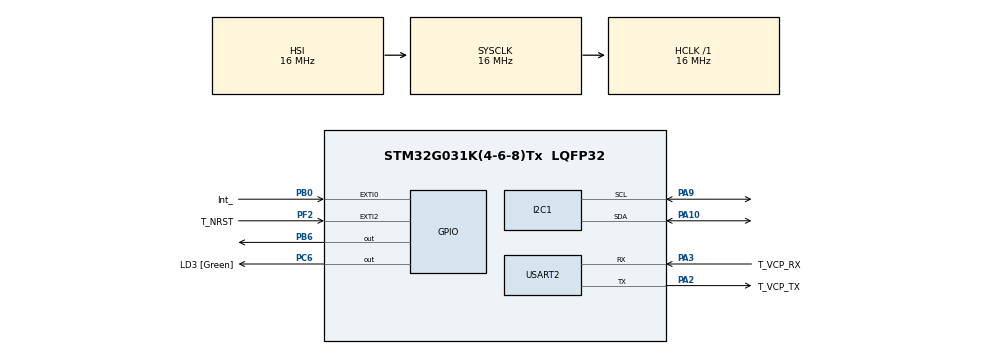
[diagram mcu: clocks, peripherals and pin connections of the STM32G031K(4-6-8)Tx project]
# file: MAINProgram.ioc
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I2C1.Timing=0x00503D58
Mcu.Family=STM32G0
Mcu.Name=STM32G031K(4-6-8)Tx
Mcu.Package=LQFP32
NVIC.EXTI0_1_IRQn=true\:0\:0\:false\:false\:true\:true\:true\:true
PA10.Mode=I2C
PA10.Signal=I2C1_SDA
PA13.GPIO_Label=T_JTMS
PA13.Mode=Serial_Wire
PA13.Signal=SYS_SWDIO
PA14-BOOT0.GPIO_Label=T_JTCK
PA14-BOOT0.Mode=Serial_Wire
PA14-BOOT0.Signal=SYS_SWCLK
PA2.GPIO_Label=T_VCP_TX
PA2.GPIO_PuPd=GPIO_PULLUP
PA2.Mode=Asynchronous
PA2.Signal=USART2_TX
PA3.GPIO_Label=T_VCP_RX
PA3.GPIO_PuPd=GPIO_PULLUP
PA3.Mode=Asynchronous
PA3.Signal=USART2_RX
PA9.Mode=I2C
PA9.Signal=I2C1_SCL
PB0.GPIO_Label=Int_
PB0.GPIO_ModeDefaultEXTI=GPIO_MODE_IT_FALLING
PB0.GPIO_PuPd=GPIO_PULLUP
PB0.Signal=GPXTI0
PB6.Signal=GPIO_Output
PC14-OSC32_IN\ (PC14).Mode=LSE-External-Oscillator
PC14-OSC32_IN\ (PC14).Signal=RCC_OSC32_IN
PC15-OSC32_OUT\ (PC15).Mode=LSE-External-Oscillator
PC15-OSC32_OUT\ (PC15).Signal=RCC_OSC32_OUT
PC6.GPIO_Label=LD3 [Green]
PC6.Signal=GPIO_Output
PF2\ -\ NRST.GPIO_Label=T_NRST
PF2\ -\ NRST.GPIO_ModeDefaultEXTI=GPIO_MODE_IT_RISING
PF2\ -\ NRST.Signal=GPXTI2
ProjectManager.HeapSize=0x200
ProjectManager.StackSize=0x400
ProjectManager.TargetToolchain=EWARM V8.50
RCC.ADCFreq_Value=16000000
RCC.AHBFreq_Value=16000000
RCC.CortexFreq_Value=16000000
RCC.EXTERNAL_CLOCK_VALUE=12288000
RCC.HCLKFreq_Value=16000000
RCC.HSE_VALUE=8000000
RCC.HSI_VALUE=16000000
RCC.SYSCLKFreq_VALUE=16000000
RCC.VCOOutputFreq_Value=128000000
USART2.VirtualMode-Asynchronous=VM_ASYNC
board=NUCLEO-G031K8

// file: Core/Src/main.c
/* USER CODE BEGIN Header */
/**
 ******************************************************************************
 * @file           : main.c
 * @brief          : Main program body
 ******************************************************************************
 * @attention
 *
 * Copyright (c) 2025 STMicroelectronics.
 * All rights reserved.
 *
 * This software is licensed under terms that can be found in the LICENSE file
 * in the root directory of this software component.
 * If no LICENSE file comes with this software, it is provided AS-IS.
 *
 ******************************************************************************
 */
/* USER CODE END Header */
#include "main.h"
#include "max30100_for_stm32_hal.h"
#include "ssd1306.h"
#include "ssd1306_fonts.h"
#include "stdio.h"

/* USER CODE BEGIN Includes */

// 'frame_00_delay-0', 32x32px
const unsigned char epd_bitmap_frame_00_delay_0[] = {
    0xff, 0xff, 0xff, 0xff, 0xff, 0xff, 0xff, 0xff, 0xff, 0xff, 0xff, 0xff, 0xff, 0xff, 0xff, 0xff,
    0xff, 0xff, 0xff, 0xff, 0xff, 0xff, 0xff, 0xff, 0xff, 0x83, 0xe0, 0xff, 0xff, 0x83, 0xe0, 0xff,
    0xff, 0x00, 0xc0, 0x7f, 0xfe, 0x00, 0x80, 0x3f, 0xfc, 0x70, 0x00, 0x1f, 0xf0, 0xf0, 0x00, 0x07,
    0xf0, 0xc0, 0x00, 0x07, 0xf0, 0xc0, 0x00, 0x07, 0xf0, 0x00, 0x00, 0x07, 0xf8, 0x00, 0x00, 0x07,
    0xfc, 0x00, 0x00, 0x1f, 0xff, 0x00, 0x00, 0x3f, 0xff, 0x00, 0x00, 0x7f, 0xff, 0x80, 0x00, 0xff,
    0xff, 0xc0, 0x01, 0xff, 0xff, 0xe0, 0x03, 0xff, 0xff, 0xf8, 0x07, 0xff, 0xff, 0xf8, 0x0f, 0xff,
    0xff, 0xfc, 0x1f, 0xff, 0xff, 0xff, 0x3f, 0xff, 0xff, 0xff, 0x7f, 0xff, 0xff, 0xff, 0xff, 0xff,
    0xff, 0xff, 0xff, 0xff, 0xff, 0xff, 0xff, 0xff, 0xff, 0xff, 0xff, 0xff, 0xff, 0xff, 0xff, 0xff};
// 'frame_01_delay-0', 32x32px
const unsigned char epd_bitmap_frame_01_delay_0[] = {
    0xff, 0xff, 0xff, 0xff, 0xff, 0xff, 0xff, 0xff, 0xff, 0xff, 0xff, 0xff, 0xff, 0xff, 0xff, 0xff,
    0xff, 0xff, 0xff, 0xff, 0xff, 0xff, 0xff, 0xff, 0xff, 0x83, 0xe0, 0xff, 0xff, 0x83, 0xe0, 0xff,
    0xff, 0x00, 0xc0, 0x7f, 0xfe, 0x00, 0x80, 0x3f, 0xfc, 0x70, 0x00, 0x1f, 0xf0, 0xf0, 0x00, 0x07,
    0xf0, 0xc0, 0x00, 0x07, 0xf0, 0xc0, 0x00, 0x07, 0xf0, 0x00, 0x00, 0x07, 0xf8, 0x00, 0x00, 0x07,
    0xfc, 0x00, 0x00, 0x1f, 0xff, 0x00, 0x00, 0x3f, 0xff, 0x00, 0x00, 0x7f, 0xff, 0x80, 0x00, 0xff,
    0xff, 0xc0, 0x01, 0xff, 0xff, 0xe0, 0x03, 0xff, 0xff, 0xf8, 0x07, 0xff, 0xff, 0xf8, 0x0f, 0xff,
    0xff, 0xfc, 0x1f, 0xff, 0xff, 0xff, 0x3f, 0xff, 0xff, 0xff, 0x7f, 0xff, 0xff, 0xff, 0xff, 0xff,
    0xff, 0xff, 0xff, 0xff, 0xff, 0xff, 0xff, 0xff, 0xff, 0xff, 0xff, 0xff, 0xff, 0xff, 0xff, 0xff};
// 'frame_02_delay-0', 32x32px
const unsigned char epd_bitmap_frame_02_delay_0[] = {
    0xff, 0xff, 0xff, 0xff, 0xff, 0xff, 0xff, 0xff, 0xff, 0xff, 0xff, 0xff, 0xff, 0xff, 0xff, 0xff,
    0xff, 0xff, 0xff, 0xff, 0xff, 0xff, 0xff, 0xff, 0xff, 0x83, 0xe0, 0xff, 0xff, 0x83, 0xe0, 0xff,
    0xff, 0x00, 0xc0, 0x7f, 0xfe, 0x00, 0x80, 0x3f, 0xfc, 0x70, 0x00, 0x1f, 0xf0, 0xf0, 0x00, 0x07,
    0xf0, 0xc0, 0x00, 0x07, 0xf0, 0xc0, 0x00, 0x07, 0xf0, 0x00, 0x00, 0x07, 0xf8, 0x00, 0x00, 0x07,
    0xfc, 0x00, 0x00, 0x1f, 0xff, 0x00, 0x00, 0x3f, 0xff, 0x00, 0x00, 0x7f, 0xff, 0x80, 0x00, 0xff,
    0xff, 0xc0, 0x01, 0xff, 0xff, 0xe0, 0x03, 0xff, 0xff, 0xf8, 0x07, 0xff, 0xff, 0xf8, 0x0f, 0xff,
    0xff, 0xfc, 0x1f, 0xff, 0xff, 0xff, 0x3f, 0xff, 0xff, 0xff, 0x7f, 0xff, 0xff, 0xff, 0xff, 0xff,
    0xff, 0xff, 0xff, 0xff, 0xff, 0xff, 0xff, 0xff, 0xff, 0xff, 0xff, 0xff, 0xff, 0xff, 0xff, 0xff};
// 'frame_03_delay-0', 32x32px
const unsigned char epd_bitmap_frame_03_delay_0[] = {
    0xff, 0xff, 0xff, 0xff, 0xff, 0xff, 0xff, 0xff, 0xff, 0xff, 0xff, 0xff, 0xff, 0xff, 0xff, 0xff,
    0xff, 0xff, 0xff, 0xff, 0xff, 0xff, 0xff, 0xff, 0xff, 0x83, 0xe0, 0xff, 0xff, 0x83, 0xe0, 0xff,
    0xff, 0x00, 0xc0, 0x7f, 0xfe, 0x00, 0x80, 0x3f, 0xfc, 0x70, 0x00, 0x1f, 0xf0, 0xf0, 0x00, 0x07,
    0xf0, 0xc0, 0x00, 0x07, 0xf0, 0xc0, 0x00, 0x07, 0xf0, 0x00, 0x00, 0x07, 0xf8, 0x00, 0x00, 0x07,
    0xfc, 0x00, 0x00, 0x1f, 0xff, 0x00, 0x00, 0x3f, 0xff, 0x00, 0x00, 0x7f, 0xff, 0x80, 0x00, 0xff,
    0xff, 0xc0, 0x01, 0xff, 0xff, 0xe0, 0x03, 0xff, 0xff, 0xf8, 0x07, 0xff, 0xff, 0xf8, 0x0f, 0xff,
    0xff, 0xfc, 0x1f, 0xff, 0xff, 0xff, 0x3f, 0xff, 0xff, 0xff, 0x7f, 0xff, 0xff, 0xff, 0xff, 0xff,
    0xff, 0xff, 0xff, 0xff, 0xff, 0xff, 0xff, 0xff, 0xff, 0xff, 0xff, 0xff, 0xff, 0xff, 0xff, 0xff};
// 'frame_04_delay-0', 32x32px
const unsigned char epd_bitmap_frame_04_delay_0[] = {
    0xff, 0xff, 0xff, 0xff, 0xff, 0xff, 0xff, 0xff, 0xff, 0xff, 0xff, 0xff, 0xff, 0xff, 0xff, 0xff,
    0xff, 0xff, 0xff, 0xff, 0xff, 0xff, 0xff, 0xff, 0xff, 0x83, 0xe0, 0xff, 0xff, 0x83, 0xe0, 0xff,
    0xff, 0x00, 0xc0, 0x7f, 0xfe, 0x00, 0x80, 0x3f, 0xfc, 0x70, 0x00, 0x1f, 0xf0, 0xf0, 0x00, 0x07,
    0xf0, 0xc0, 0x00, 0x07, 0xf0, 0xc0, 0x00, 0x07, 0xf0, 0x00, 0x00, 0x07, 0xf8, 0x00, 0x00, 0x07,
    0xfc, 0x00, 0x00, 0x1f, 0xff, 0x00, 0x00, 0x3f, 0xff, 0x00, 0x00, 0x7f, 0xff, 0x80, 0x00, 0xff,
    0xff, 0xc0, 0x01, 0xff, 0xff, 0xe0, 0x03, 0xff, 0xff, 0xf8, 0x07, 0xff, 0xff, 0xf8, 0x0f, 0xff,
    0xff, 0xfc, 0x1f, 0xff, 0xff, 0xff, 0x3f, 0xff, 0xff, 0xff, 0x7f, 0xff, 0xff, 0xff, 0xff, 0xff,
    0xff, 0xff, 0xff, 0xff, 0xff, 0xff, 0xff, 0xff, 0xff, 0xff, 0xff, 0xff, 0xff, 0xff, 0xff, 0xff};
// 'frame_05_delay-0', 32x32px
const unsigned char epd_bitmap_frame_05_delay_0[] = {
    0xff, 0xff, 0xff, 0xff, 0xff, 0xff, 0xff, 0xff, 0xff, 0xff, 0xff, 0xff, 0xff, 0xff, 0xff, 0xff,
    0xff, 0xff, 0xff, 0xff, 0xff, 0xff, 0xff, 0xff, 0xff, 0x83, 0xe0, 0xff, 0xff, 0x83, 0xe0, 0xff,
    0xff, 0x00, 0xc0, 0x7f, 0xfe, 0x00, 0x80, 0x3f, 0xfc, 0x70, 0x00, 0x1f, 0xf0, 0xf0, 0x00, 0x07,
    0xf0, 0xc0, 0x00, 0x07, 0xf0, 0xc0, 0x00, 0x07, 0xf0, 0x00, 0x00, 0x07, 0xf8, 0x00, 0x00, 0x07,
    0xfc, 0x00, 0x00, 0x1f, 0xff, 0x00, 0x00, 0x3f, 0xff, 0x00, 0x00, 0x7f, 0xff, 0x80, 0x00, 0xff,
    0xff, 0xc0, 0x01, 0xff, 0xff, 0xe0, 0x03, 0xff, 0xff, 0xf8, 0x07, 0xff, 0xff, 0xf8, 0x0f, 0xff,
    0xff, 0xfc, 0x1f, 0xff, 0xff, 0xff, 0x3f, 0xff, 0xff, 0xff, 0x7f, 0xff, 0xff, 0xff, 0xff, 0xff,
    0xff, 0xff, 0xff, 0xff, 0xff, 0xff, 0xff, 0xff, 0xff, 0xff, 0xff, 0xff, 0xff, 0xff, 0xff, 0xff};
// 'frame_06_delay-0', 32x32px
const unsigned char epd_bitmap_frame_06_delay_0[] = {
    0xff, 0xff, 0xff, 0xff, 0xff, 0xff, 0xff, 0xff, 0xff, 0xff, 0xff, 0xff, 0xff, 0xff, 0xff, 0xff,
    0xff, 0xff, 0xff, 0xff, 0xff, 0xff, 0xff, 0xff, 0xff, 0x83, 0xe0, 0xff, 0xff, 0x83, 0xe0, 0xff,
    0xff, 0x00, 0xc0, 0x7f, 0xfe, 0x00, 0x80, 0x3f, 0xfc, 0x70, 0x00, 0x1f, 0xf0, 0xf0, 0x00, 0x07,
    0xf0, 0xc0, 0x00, 0x07, 0xf0, 0xc0, 0x00, 0x07, 0xf0, 0x00, 0x00, 0x07, 0xf8, 0x00, 0x00, 0x07,
    0xfc, 0x00, 0x00, 0x1f, 0xff, 0x00, 0x00, 0x3f, 0xff, 0x00, 0x00, 0x7f, 0xff, 0x80, 0x00, 0xff,
    0xff, 0xc0, 0x01, 0xff, 0xff, 0xe0, 0x03, 0xff, 0xff, 0xf8, 0x07, 0xff, 0xff, 0xf8, 0x0f, 0xff,
    0xff, 0xfc, 0x1f, 0xff, 0xff, 0xff, 0x3f, 0xff, 0xff, 0xff, 0x7f, 0xff, 0xff, 0xff, 0xff, 0xff,
    0xff, 0xff, 0xff, 0xff, 0xff, 0xff, 0xff, 0xff, 0xff, 0xff, 0xff, 0xff, 0xff, 0xff, 0xff, 0xff};
// 'frame_07_delay-0', 32x32px
const unsigned char epd_bitmap_frame_07_delay_0[] = {
    0xff, 0xff, 0xff, 0xff, 0xff, 0xff, 0xff, 0xff, 0xff, 0xff, 0xff, 0xff, 0xff, 0xff, 0xff, 0xff,
    0xff, 0xff, 0xff, 0xff, 0xff, 0xff, 0xff, 0xff, 0xff, 0x83, 0xe0, 0xff, 0xff, 0x83, 0xe0, 0xff,
    0xff, 0x00, 0xc0, 0x7f, 0xfe, 0x00, 0x80, 0x3f, 0xfc, 0x70, 0x00, 0x1f, 0xf0, 0xf0, 0x00, 0x07,
    0xf0, 0xc0, 0x00, 0x07, 0xf0, 0xc0, 0x00, 0x07, 0xf0, 0x00, 0x00, 0x07, 0xf8, 0x00, 0x00, 0x07,
    0xfc, 0x00, 0x00, 0x1f, 0xff, 0x00, 0x00, 0x3f, 0xff, 0x00, 0x00, 0x7f, 0xff, 0x80, 0x00, 0xff,
    0xff, 0xc0, 0x01, 0xff, 0xff, 0xe0, 0x03, 0xff, 0xff, 0xf8, 0x07, 0xff, 0xff, 0xf8, 0x0f, 0xff,
    0xff, 0xfc, 0x1f, 0xff, 0xff, 0xff, 0x3f, 0xff, 0xff, 0xff, 0x7f, 0xff, 0xff, 0xff, 0xff, 0xff,
    0xff, 0xff, 0xff, 0xff, 0xff, 0xff, 0xff, 0xff, 0xff, 0xff, 0xff, 0xff, 0xff, 0xff, 0xff, 0xff};
// 'frame_08_delay-0', 32x32px
const unsigned char epd_bitmap_frame_08_delay_0[] = {
    0xff, 0xff, 0xff, 0xff, 0xff, 0xff, 0xff, 0xff, 0xff, 0xff, 0xff, 0xff, 0xff, 0xff, 0xff, 0xff,
    0xff, 0xff, 0xff, 0xff, 0xff, 0xff, 0xff, 0xff, 0xff, 0x83, 0xe0, 0xff, 0xff, 0x83, 0xe0, 0xff,
    0xff, 0x00, 0xc0, 0x7f, 0xfe, 0x00, 0x80, 0x3f, 0xfc, 0x70, 0x00, 0x1f, 0xf0, 0xf0, 0x00, 0x07,
    0xf0, 0xc0, 0x00, 0x07, 0xf0, 0xc0, 0x00, 0x07, 0xf0, 0x00, 0x00, 0x07, 0xf8, 0x00, 0x00, 0x07,
    0xfc, 0x00, 0x00, 0x1f, 0xff, 0x00, 0x00, 0x3f, 0xff, 0x00, 0x00, 0x7f, 0xff, 0x80, 0x00, 0xff,
    0xff, 0xc0, 0x01, 0xff, 0xff, 0xe0, 0x03, 0xff, 0xff, 0xf8, 0x07, 0xff, 0xff, 0xf8, 0x0f, 0xff,
    0xff, 0xfc, 0x1f, 0xff, 0xff, 0xff, 0x3f, 0xff, 0xff, 0xff, 0x7f, 0xff, 0xff, 0xff, 0xff, 0xff,
    0xff, 0xff, 0xff, 0xff, 0xff, 0xff, 0xff, 0xff, 0xff, 0xff, 0xff, 0xff, 0xff, 0xff, 0xff, 0xff};
// 'frame_09_delay-0', 32x32px
const unsigned char epd_bitmap_frame_09_delay_0[] = {
    0xff, 0xff, 0xff, 0xff, 0xff, 0xff, 0xff, 0xff, 0xff, 0xff, 0xff, 0xff, 0xff, 0xff, 0xff, 0xff,
    0xff, 0xff, 0xff, 0xff, 0xff, 0xff, 0xff, 0xff, 0xff, 0x83, 0xe0, 0xff, 0xff, 0x83, 0xe0, 0xff,
    0xff, 0x00, 0xc0, 0x7f, 0xfe, 0x00, 0x80, 0x3f, 0xfc, 0x70, 0x00, 0x1f, 0xf0, 0xf0, 0x00, 0x07,
    0xf0, 0xc0, 0x00, 0x07, 0xf0, 0xc0, 0x00, 0x07, 0xf0, 0x00, 0x00, 0x07, 0xf8, 0x00, 0x00, 0x07,
    0xfc, 0x00, 0x00, 0x1f, 0xff, 0x00, 0x00, 0x3f, 0xff, 0x00, 0x00, 0x7f, 0xff, 0x80, 0x00, 0xff,
    0xff, 0xc0, 0x01, 0xff, 0xff, 0xe0, 0x03, 0xff, 0xff, 0xf8, 0x07, 0xff, 0xff, 0xf8, 0x0f, 0xff,
    0xff, 0xfc, 0x1f, 0xff, 0xff, 0xff, 0x3f, 0xff, 0xff, 0xff, 0x7f, 0xff, 0xff, 0xff, 0xff, 0xff,
    0xff, 0xff, 0xff, 0xff, 0xff, 0xff, 0xff, 0xff, 0xff, 0xff, 0xff, 0xff, 0xff, 0xff, 0xff, 0xff};
// 'frame_10_delay-0', 32x32px
const unsigned char epd_bitmap_frame_10_delay_0[] = {
    0xff, 0xff, 0xff, 0xff, 0xff, 0xff, 0xff, 0xff, 0xff, 0xff, 0xff, 0xff, 0xff, 0xff, 0xff, 0xff,
    0xff, 0xff, 0xff, 0xff, 0xff, 0xff, 0xff, 0xff, 0xff, 0x83, 0xe0, 0xff, 0xff, 0x83, 0xe0, 0xff,
    0xff, 0x00, 0xc0, 0x7f, 0xfe, 0x00, 0x80, 0x3f, 0xfc, 0x70, 0x00, 0x1f, 0xf0, 0xf0, 0x00, 0x07,
    0xf0, 0xc0, 0x00, 0x07, 0xf0, 0xc0, 0x00, 0x07, 0xf0, 0x00, 0x00, 0x07, 0xf8, 0x00, 0x00, 0x07,
    0xfc, 0x00, 0x00, 0x1f, 0xff, 0x00, 0x00, 0x3f, 0xff, 0x00, 0x00, 0x7f, 0xff, 0x80, 0x00, 0xff,
    0xff, 0xc0, 0x01, 0xff, 0xff, 0xe0, 0x03, 0xff, 0xff, 0xf8, 0x07, 0xff, 0xff, 0xf8, 0x0f, 0xff,
    0xff, 0xfc, 0x1f, 0xff, 0xff, 0xff, 0x3f, 0xff, 0xff, 0xff, 0x7f, 0xff, 0xff, 0xff, 0xff, 0xff,
    0xff, 0xff, 0xff, 0xff, 0xff, 0xff, 0xff, 0xff, 0xff, 0xff, 0xff, 0xff, 0xff, 0xff, 0xff, 0xff};
// 'frame_11_delay-0', 32x32px
const unsigned char epd_bitmap_frame_11_delay_0[] = {
    0xff, 0xff, 0xff, 0xff, 0xff, 0xff, 0xff, 0xff, 0xff, 0xff, 0xff, 0xff, 0xff, 0xff, 0xff, 0xff,
    0xff, 0xff, 0xff, 0xff, 0xff, 0xff, 0xff, 0xff, 0xff, 0x83, 0xe0, 0xff, 0xff, 0x83, 0xe0, 0xff,
    0xff, 0x00, 0xc0, 0x7f, 0xfe, 0x00, 0x80, 0x3f, 0xfc, 0x70, 0x00, 0x1f, 0xf0, 0xf0, 0x00, 0x07,
    0xf0, 0xc0, 0x00, 0x07, 0xf0, 0xc0, 0x00, 0x07, 0xf0, 0x00, 0x00, 0x07, 0xf8, 0x00, 0x00, 0x07,
    0xfc, 0x00, 0x00, 0x1f, 0xff, 0x00, 0x00, 0x3f, 0xff, 0x00, 0x00, 0x7f, 0xff, 0x80, 0x00, 0xff,
    0xff, 0xc0, 0x01, 0xff, 0xff, 0xe0, 0x03, 0xff, 0xff, 0xf8, 0x07, 0xff, 0xff, 0xf8, 0x0f, 0xff,
    0xff, 0xfc, 0x1f, 0xff, 0xff, 0xff, 0x3f, 0xff, 0xff, 0xff, 0x7f, 0xff, 0xff, 0xff, 0xff, 0xff,
    0xff, 0xff, 0xff, 0xff, 0xff, 0xff, 0xff, 0xff, 0xff, 0xff, 0xff, 0xff, 0xff, 0xff, 0xff, 0xff};
// 'frame_12_delay-0', 32x32px
const unsigned char epd_bitmap_frame_12_delay_0[] = {
    0xff, 0xff, 0xff, 0xff, 0xff, 0xff, 0xff, 0xff, 0xff, 0xff, 0xff, 0xff, 0xff, 0xff, 0xff, 0xff,
    0xff, 0xff, 0xff, 0xff, 0xff, 0xff, 0xff, 0xff, 0xff, 0x83, 0xe0, 0xff, 0xff, 0x83, 0xe0, 0x7f,
    0xfe, 0x01, 0xc0, 0x3f, 0xfc, 0x70, 0x00, 0x1f, 0xfc, 0x70, 0x00, 0x1f, 0xf0, 0xf0, 0x00, 0x07,
    0xf0, 0xc0, 0x00, 0x07, 0xf0, 0xc0, 0x00, 0x07, 0xf0, 0x00, 0x00, 0x07, 0xf0, 0x00, 0x00, 0x07,
    0xfc, 0x00, 0x00, 0x1f, 0xfe, 0x00, 0x00, 0x3f, 0xfe, 0x00, 0x00, 0x3f, 0xff, 0x80, 0x00, 0xff,
    0xff, 0x80, 0x00, 0xff, 0xff, 0xe0, 0x03, 0xff, 0xff, 0xf0, 0x07, 0xff, 0xff, 0xf8, 0x07, 0xff,
    0xff, 0xfc, 0x1f, 0xff, 0xff, 0xfc, 0x1f, 0xff, 0xff, 0xff, 0x7f, 0xff, 0xff, 0xff, 0xff, 0xff,
    0xff, 0xff, 0xff, 0xff, 0xff, 0xff, 0xff, 0xff, 0xff, 0xff, 0xff, 0xff, 0xff, 0xff, 0xff, 0xff};
// 'frame_14_delay-0', 32x32px
const unsigned char epd_bitmap_frame_14_delay_0[] = {
    0xff, 0xff, 0xff, 0xff, 0xff, 0xff, 0xff, 0xff, 0xff, 0xff, 0xff, 0xff, 0xff, 0xff, 0xff, 0xff,
    0xff, 0xff, 0xff, 0xff, 0xff, 0x83, 0xf0, 0x7f, 0xff, 0x83, 0xf0, 0x7f, 0xfe, 0x01, 0xc0, 0x3f,
    0xfe, 0x00, 0xc0, 0x1f, 0xf8, 0x70, 0x00, 0x0f, 0xf8, 0x70, 0x00, 0x07, 0xe1, 0xe0, 0x00, 0x03,
    0xe1, 0xc0, 0x00, 0x03, 0xe0, 0x00, 0x00, 0x03, 0xe0, 0x00, 0x00, 0x03, 0xf0, 0x00, 0x00, 0x07,
    0xf8, 0x00, 0x00, 0x0f, 0xfe, 0x00, 0x00, 0x1f, 0xfe, 0x00, 0x00, 0x3f, 0xff, 0x80, 0x00, 0x7f,
    0xff, 0x80, 0x00, 0x7f, 0xff, 0xe0, 0x01, 0xff, 0xff, 0xe0, 0x01, 0xff, 0xff, 0xf0, 0x07, 0xff,
    0xff, 0xf0, 0x07, 0xff, 0xff, 0xfc, 0x1f, 0xff, 0xff, 0xff, 0x3f, 0xff, 0xff, 0xff, 0x7f, 0xff,
    0xff, 0xff, 0xff, 0xff, 0xff, 0xff, 0xff, 0xff, 0xff, 0xff, 0xff, 0xff, 0xff, 0xff, 0xff, 0xff};
// 'frame_13_delay-0', 32x32px
const unsigned char epd_bitmap_frame_13_delay_0[] = {
    0xff, 0xff, 0xff, 0xff, 0xff, 0xff, 0xff, 0xff, 0xff, 0xff, 0xff, 0xff, 0xff, 0xff, 0xff, 0xff,
    0xff, 0xff, 0xff, 0xff, 0xff, 0x87, 0xf0, 0xff, 0xff, 0x83, 0xf0, 0xff, 0xfe, 0x01, 0xc0, 0x3f,
    0xfe, 0x00, 0xc0, 0x3f, 0xf8, 0x70, 0x00, 0x0f, 0xf8, 0x70, 0x00, 0x0f, 0xf1, 0xf0, 0x00, 0x03,
    0xf1, 0xc0, 0x00, 0x03, 0xf0, 0xc0, 0x00, 0x03, 0xf0, 0x00, 0x00, 0x03, 0xf0, 0x00, 0x00, 0x07,
    0xf8, 0x00, 0x00, 0x0f, 0xfe, 0x00, 0x00, 0x3f, 0xfe, 0x00, 0x00, 0x3f, 0xff, 0x80, 0x00, 0xff,
    0xff, 0x80, 0x00, 0xff, 0xff, 0xe0, 0x03, 0xff, 0xff, 0xe0, 0x03, 0xff, 0xff, 0xf0, 0x07, 0xff,
    0xff, 0xfc, 0x1f, 0xff, 0xff, 0xfc, 0x1f, 0xff, 0xff, 0xff, 0x7f, 0xff, 0xff, 0xff, 0x7f, 0xff,
    0xff, 0xff, 0xff, 0xff, 0xff, 0xff, 0xff, 0xff, 0xff, 0xff, 0xff, 0xff, 0xff, 0xff, 0xff, 0xff};
// 'frame_15_delay-0', 32x32px
const unsigned char epd_bitmap_frame_15_delay_0[] = {
    0xff, 0xff, 0xff, 0xff, 0xff, 0xff, 0xff, 0xff, 0xff, 0xff, 0xff, 0xff, 0xff, 0xff, 0xff, 0xff,
    0xff, 0xff, 0xff, 0xff, 0xff, 0x03, 0xf0, 0x7f, 0xff, 0x03, 0xe0, 0x7f, 0xfe, 0x01, 0xc0, 0x1f,
    0xfc, 0x00, 0x80, 0x1f, 0xf8, 0x60, 0x00, 0x0f, 0xe0, 0x60, 0x00, 0x03, 0xe1, 0xc0, 0x00, 0x03,
    0xe1, 0xc0, 0x00, 0x03, 0xe0, 0x00, 0x00, 0x03, 0xe0, 0x00, 0x00, 0x03, 0xf0, 0x00, 0x00, 0x07,
    0xf8, 0x00, 0x00, 0x0f, 0xfc, 0x00, 0x00, 0x1f, 0xfe, 0x00, 0x00, 0x1f, 0xff, 0x00, 0x00, 0x7f,
    0xff, 0x00, 0x00, 0x7f, 0xff, 0xc0, 0x01, 0xff, 0xff, 0xc0, 0x01, 0xff, 0xff, 0xf0, 0x07, 0xff,
    0xff, 0xf0, 0x07, 0xff, 0xff, 0xfc, 0x1f, 0xff, 0xff, 0xfc, 0x1f, 0xff, 0xff, 0xff, 0x7f, 0xff,
    0xff, 0xff, 0x7f, 0xff, 0xff, 0xff, 0xff, 0xff, 0xff, 0xff, 0xff, 0xff, 0xff, 0xff, 0xff, 0xff};
// 'frame_17_delay-0', 32x32px
const unsigned char epd_bitmap_frame_17_delay_0[] = {
    0xff, 0xff, 0xff, 0xff, 0xff, 0xff, 0xff, 0xff, 0xff, 0xff, 0xff, 0xff, 0xff, 0xff, 0xff, 0xff,
    0xff, 0x07, 0xf0, 0x7f, 0xff, 0x07, 0xf0, 0x7f, 0xfc, 0x01, 0xc0, 0x1f, 0xfc, 0x01, 0xc0, 0x1f,
    0xf0, 0xe0, 0x00, 0x07, 0xf0, 0xe0, 0x00, 0x07, 0xc3, 0xe0, 0x00, 0x01, 0xc3, 0x80, 0x00, 0x01,
    0xc3, 0x80, 0x00, 0x01, 0xc0, 0x00, 0x00, 0x01, 0xc0, 0x00, 0x00, 0x01, 0xf0, 0x00, 0x00, 0x03,
    0xf0, 0x00, 0x00, 0x07, 0xfc, 0x00, 0x00, 0x0f, 0xfc, 0x00, 0x00, 0x1f, 0xff, 0x00, 0x00, 0x3f,
    0xff, 0x00, 0x00, 0x7f, 0xff, 0xc0, 0x01, 0xff, 0xff, 0xc0, 0x01, 0xff, 0xff, 0xf0, 0x07, 0xff,
    0xff, 0xf0, 0x07, 0xff, 0xff, 0xfc, 0x1f, 0xff, 0xff, 0xfc, 0x1f, 0xff, 0xff, 0xff, 0x7f, 0xff,
    0xff, 0xff, 0x7f, 0xff, 0xff, 0xff, 0xff, 0xff, 0xff, 0xff, 0xff, 0xff, 0xff, 0xff, 0xff, 0xff};
// 'frame_16_delay-0', 32x32px
const unsigned char epd_bitmap_frame_16_delay_0[] = {
    0xff, 0xff, 0xff, 0xff, 0xff, 0xff, 0xff, 0xff, 0xff, 0xff, 0xff, 0xff, 0xff, 0xff, 0xff, 0xff,
    0xff, 0x07, 0xf0, 0x7f, 0xff, 0x07, 0xf0, 0x7f, 0xfc, 0x01, 0xc0, 0x1f, 0xfc, 0x01, 0xc0, 0x1f,
    0xf0, 0x60, 0x00, 0x07, 0xf0, 0xe0, 0x00, 0x07, 0xc1, 0xe0, 0x00, 0x01, 0xc3, 0x80, 0x00, 0x01,
    0xc3, 0x80, 0x00, 0x01, 0xc0, 0x00, 0x00, 0x01, 0xc0, 0x00, 0x00, 0x01, 0xf0, 0x00, 0x00, 0x07,
    0xf0, 0x00, 0x00, 0x07, 0xfc, 0x00, 0x00, 0x1f, 0xfc, 0x00, 0x00, 0x1f, 0xff, 0x00, 0x00, 0x7f,
    0xff, 0x00, 0x00, 0x7f, 0xff, 0xc0, 0x01, 0xff, 0xff, 0xc0, 0x01, 0xff, 0xff, 0xf0, 0x07, 0xff,
    0xff, 0xf0, 0x07, 0xff, 0xff, 0xfc, 0x1f, 0xff, 0xff, 0xfc, 0x1f, 0xff, 0xff, 0xff, 0x7f, 0xff,
    0xff, 0xff, 0x7f, 0xff, 0xff, 0xff, 0xff, 0xff, 0xff, 0xff, 0xff, 0xff, 0xff, 0xff, 0xff, 0xff};
// 'frame_18_delay-0', 32x32px
const unsigned char epd_bitmap_frame_18_delay_0[] = {
    0xff, 0xff, 0xff, 0xff, 0xff, 0xff, 0xff, 0xff, 0xff, 0xff, 0xff, 0xff, 0xff, 0xff, 0xff, 0xff,
    0xff, 0x07, 0xf0, 0x7f, 0xff, 0x03, 0xf0, 0x3f, 0xfc, 0x01, 0xc0, 0x0f, 0xfc, 0x00, 0xc0, 0x0f,
    0xf0, 0xe0, 0x00, 0x03, 0xf0, 0xe0, 0x00, 0x03, 0xc3, 0xe0, 0x00, 0x00, 0xc3, 0x80, 0x00, 0x00,
    0xc3, 0x80, 0x00, 0x00, 0xc0, 0x00, 0x00, 0x00, 0xc0, 0x00, 0x00, 0x00, 0xe0, 0x00, 0x00, 0x03,
    0xf0, 0x00, 0x00, 0x03, 0xf8, 0x00, 0x00, 0x0f, 0xfc, 0x00, 0x00, 0x0f, 0xfe, 0x00, 0x00, 0x3f,
    0xff, 0x00, 0x00, 0x7f, 0xff, 0x80, 0x00, 0xff, 0xff, 0xc0, 0x01, 0xff, 0xff, 0xc0, 0x01, 0xff,
    0xff, 0xf0, 0x07, 0xff, 0xff, 0xf0, 0x07, 0xff, 0xff, 0xfc, 0x1f, 0xff, 0xff, 0xfc, 0x1f, 0xff,
    0xff, 0xff, 0x7f, 0xff, 0xff, 0xff, 0x7f, 0xff, 0xff, 0xff, 0xff, 0xff, 0xff, 0xff, 0xff, 0xff};
// 'frame_20_delay-0', 32x32px
const unsigned char epd_bitmap_frame_20_delay_0[] = {
    0xff, 0xff, 0xff, 0xff, 0xff, 0xff, 0xff, 0xff, 0xff, 0xff, 0xff, 0xff, 0xff, 0xff, 0xff, 0xff,
    0xff, 0x07, 0xf0, 0x7f, 0xff, 0x07, 0xf0, 0x7f, 0xfc, 0x01, 0xc0, 0x1f, 0xfc, 0x01, 0xc0, 0x1f,
    0xf0, 0xe0, 0x00, 0x07, 0xf0, 0xe0, 0x00, 0x07, 0xc3, 0xe0, 0x00, 0x01, 0xc3, 0x80, 0x00, 0x01,
    0xc3, 0x80, 0x00, 0x01, 0xc0, 0x00, 0x00, 0x01, 0xc0, 0x00, 0x00, 0x01, 0xf0, 0x00, 0x00, 0x03,
    0xf0, 0x00, 0x00, 0x07, 0xfc, 0x00, 0x00, 0x0f, 0xfc, 0x00, 0x00, 0x1f, 0xff, 0x00, 0x00, 0x3f,
    0xff, 0x00, 0x00, 0x7f, 0xff, 0xc0, 0x01, 0xff, 0xff, 0xc0, 0x01, 0xff, 0xff, 0xf0, 0x07, 0xff,
    0xff, 0xf0, 0x07, 0xff, 0xff, 0xfc, 0x1f, 0xff, 0xff, 0xfc, 0x1f, 0xff, 0xff, 0xff, 0x7f, 0xff,
    0xff, 0xff, 0x7f, 0xff, 0xff, 0xff, 0xff, 0xff, 0xff, 0xff, 0xff, 0xff, 0xff, 0xff, 0xff, 0xff};
// 'frame_19_delay-0', 32x32px
const unsigned char epd_bitmap_frame_19_delay_0[] = {
    0xff, 0xff, 0xff, 0xff, 0xff, 0xff, 0xff, 0xff, 0xff, 0xff, 0xff, 0xff, 0xff, 0xff, 0xff, 0xff,
    0xff, 0x07, 0xf0, 0x7f, 0xff, 0x07, 0xf0, 0x7f, 0xfc, 0x01, 0xc0, 0x1f, 0xfc, 0x01, 0xc0, 0x1f,
    0xf0, 0xe0, 0x00, 0x07, 0xf0, 0xe0, 0x00, 0x07, 0xc3, 0xe0, 0x00, 0x01, 0xc3, 0x80, 0x00, 0x01,
    0xc3, 0x80, 0x00, 0x01, 0xc0, 0x00, 0x00, 0x01, 0xc0, 0x00, 0x00, 0x01, 0xe0, 0x00, 0x00, 0x03,
    0xf0, 0x00, 0x00, 0x07, 0xfc, 0x00, 0x00, 0x0f, 0xfc, 0x00, 0x00, 0x1f, 0xff, 0x00, 0x00, 0x3f,
    0xff, 0x00, 0x00, 0x7f, 0xff, 0xc0, 0x00, 0xff, 0xff, 0xc0, 0x01, 0xff, 0xff, 0xf0, 0x03, 0xff,
    0xff, 0xf0, 0x07, 0xff, 0xff, 0xfc, 0x0f, 0xff, 0xff, 0xfc, 0x1f, 0xff, 0xff, 0xff, 0x3f, 0xff,
    0xff, 0xff, 0x7f, 0xff, 0xff, 0xff, 0xff, 0xff, 0xff, 0xff, 0xff, 0xff, 0xff, 0xff, 0xff, 0xff};
// 'frame_23_delay-0', 32x32px
const unsigned char epd_bitmap_frame_23_delay_0[] = {
    0xff, 0xff, 0xff, 0xff, 0xff, 0xff, 0xff, 0xff, 0xff, 0xff, 0xff, 0xff, 0xff, 0xff, 0xff, 0xff,
    0xff, 0xff, 0xff, 0xff, 0xff, 0x07, 0xf0, 0x7f, 0xff, 0x03, 0xe0, 0x3f, 0xfc, 0x01, 0xc0, 0x1f,
    0xf8, 0x00, 0x00, 0x07, 0xf8, 0x60, 0x00, 0x07, 0xe0, 0xe0, 0x00, 0x01, 0xe1, 0x80, 0x00, 0x01,
    0xe1, 0x80, 0x00, 0x01, 0xe0, 0x00, 0x00, 0x01, 0xe0, 0x00, 0x00, 0x01, 0xf0, 0x00, 0x00, 0x07,
    0xf8, 0x00, 0x00, 0x07, 0xfc, 0x00, 0x00, 0x1f, 0xfc, 0x00, 0x00, 0x1f, 0xff, 0x00, 0x00, 0x7f,
    0xff, 0x00, 0x00, 0x7f, 0xff, 0xc0, 0x01, 0xff, 0xff, 0xc0, 0x01, 0xff, 0xff, 0xf0, 0x07, 0xff,
    0xff, 0xf0, 0x07, 0xff, 0xff, 0xfc, 0x1f, 0xff, 0xff, 0xfc, 0x1f, 0xff, 0xff, 0xff, 0x7f, 0xff,
    0xff, 0xff, 0x7f, 0xff, 0xff, 0xff, 0xff, 0xff, 0xff, 0xff, 0xff, 0xff, 0xff, 0xff, 0xff, 0xff};
// 'frame_24_delay-0', 32x32px
const unsigned char epd_bitmap_frame_24_delay_0[] = {
    0xff, 0xff, 0xff, 0xff, 0xff, 0xff, 0xff, 0xff, 0xff, 0xff, 0xff, 0xff, 0xff, 0xff, 0xff, 0xff,
    0xff, 0xff, 0xff, 0xff, 0xff, 0x03, 0xf0, 0x7f, 0xff, 0x03, 0xe0, 0x7f, 0xfe, 0x01, 0xc0, 0x1f,
    0xfc, 0x00, 0x80, 0x1f, 0xf8, 0x60, 0x00, 0x0f, 0xe0, 0x60, 0x00, 0x03, 0xe1, 0xc0, 0x00, 0x03,
    0xe1, 0xc0, 0x00, 0x03, 0xe0, 0x00, 0x00, 0x03, 0xe0, 0x00, 0x00, 0x03, 0xf0, 0x00, 0x00, 0x07,
    0xf8, 0x00, 0x00, 0x0f, 0xfc, 0x00, 0x00, 0x1f, 0xfe, 0x00, 0x00, 0x1f, 0xff, 0x00, 0x00, 0x7f,
    0xff, 0x00, 0x00, 0x7f, 0xff, 0xc0, 0x01, 0xff, 0xff, 0xc0, 0x01, 0xff, 0xff, 0xf0, 0x07, 0xff,
    0xff, 0xf0, 0x07, 0xff, 0xff, 0xfc, 0x1f, 0xff, 0xff, 0xfc, 0x1f, 0xff, 0xff, 0xff, 0x7f, 0xff,
    0xff, 0xff, 0x7f, 0xff, 0xff, 0xff, 0xff, 0xff, 0xff, 0xff, 0xff, 0xff, 0xff, 0xff, 0xff, 0xff};
// 'frame_22_delay-0', 32x32px
const unsigned char epd_bitmap_frame_22_delay_0[] = {
    0xff, 0xff, 0xff, 0xff, 0xff, 0xff, 0xff, 0xff, 0xff, 0xff, 0xff, 0xff, 0xff, 0xff, 0xff, 0xff,
    0xff, 0x07, 0xf0, 0x7f, 0xff, 0x07, 0xf0, 0x7f, 0xfc, 0x01, 0xc0, 0x1f, 0xfc, 0x01, 0xc0, 0x1f,
    0xf0, 0x60, 0x00, 0x07, 0xf0, 0xe0, 0x00, 0x07, 0xc1, 0xe0, 0x00, 0x01, 0xc3, 0x80, 0x00, 0x01,
    0xc3, 0x80, 0x00, 0x01, 0xc0, 0x00, 0x00, 0x01, 0xc0, 0x00, 0x00, 0x01, 0xf0, 0x00, 0x00, 0x07,
    0xf0, 0x00, 0x00, 0x07, 0xfc, 0x00, 0x00, 0x1f, 0xfc, 0x00, 0x00, 0x1f, 0xff, 0x00, 0x00, 0x7f,
    0xff, 0x00, 0x00, 0x7f, 0xff, 0xc0, 0x01, 0xff, 0xff, 0xc0, 0x01, 0xff, 0xff, 0xf0, 0x07, 0xff,
    0xff, 0xf0, 0x07, 0xff, 0xff, 0xfc, 0x1f, 0xff, 0xff, 0xfc, 0x1f, 0xff, 0xff, 0xff, 0x7f, 0xff,
    0xff, 0xff, 0x7f, 0xff, 0xff, 0xff, 0xff, 0xff, 0xff, 0xff, 0xff, 0xff, 0xff, 0xff, 0xff, 0xff};
// 'frame_25_delay-0', 32x32px
const unsigned char epd_bitmap_frame_25_delay_0[] = {
    0xff, 0xff, 0xff, 0xff, 0xff, 0xff, 0xff, 0xff, 0xff, 0xff, 0xff, 0xff, 0xff, 0xff, 0xff, 0xff,
    0xff, 0xff, 0xff, 0xff, 0xff, 0x83, 0xf0, 0x7f, 0xff, 0x03, 0xf0, 0x7f, 0xfe, 0x01, 0xc0, 0x3f,
    0xfc, 0x00, 0xc0, 0x1f, 0xf8, 0x60, 0x00, 0x0f, 0xf0, 0x60, 0x00, 0x07, 0xe1, 0xe0, 0x00, 0x03,
    0xe1, 0xc0, 0x00, 0x03, 0xe0, 0x00, 0x00, 0x03, 0xe0, 0x00, 0x00, 0x03, 0xf0, 0x00, 0x00, 0x07,
    0xf8, 0x00, 0x00, 0x0f, 0xfc, 0x00, 0x00, 0x1f, 0xfe, 0x00, 0x00, 0x3f, 0xff, 0x00, 0x00, 0x7f,
    0xff, 0x80, 0x00, 0x7f, 0xff, 0xc0, 0x01, 0xff, 0xff, 0xc0, 0x01, 0xff, 0xff, 0xf0, 0x07, 0xff,
    0xff, 0xf0, 0x07, 0xff, 0xff, 0xfc, 0x1f, 0xff, 0xff, 0xfc, 0x1f, 0xff, 0xff, 0xff, 0x7f, 0xff,
    0xff, 0xff, 0xff, 0xff, 0xff, 0xff, 0xff, 0xff, 0xff, 0xff, 0xff, 0xff, 0xff, 0xff, 0xff, 0xff};
// 'frame_28_delay-0', 32x32px
const unsigned char epd_bitmap_frame_28_delay_0[] = {
    0xff, 0xff, 0xff, 0xff, 0xff, 0xff, 0xff, 0xff, 0xff, 0xff, 0xff, 0xff, 0xff, 0xff, 0xff, 0xff,
    0xff, 0xff, 0xff, 0xff, 0xff, 0x83, 0xf0, 0x7f, 0xff, 0x83, 0xf0, 0x7f, 0xfe, 0x01, 0xc0, 0x3f,
    0xfe, 0x00, 0xc0, 0x1f, 0xf8, 0x60, 0x00, 0x0f, 0xf8, 0x70, 0x00, 0x07, 0xe1, 0xe0, 0x00, 0x03,
    0xe1, 0xc0, 0x00, 0x03, 0xe0, 0x00, 0x00, 0x03, 0xe0, 0x00, 0x00, 0x03, 0xf0, 0x00, 0x00, 0x07,
    0xf8, 0x00, 0x00, 0x0f, 0xfe, 0x00, 0x00, 0x1f, 0xfe, 0x00, 0x00, 0x3f, 0xff, 0x80, 0x00, 0x7f,
    0xff, 0x80, 0x00, 0x7f, 0xff, 0xe0, 0x01, 0xff, 0xff, 0xe0, 0x01, 0xff, 0xff, 0xf0, 0x07, 0xff,
    0xff, 0xf0, 0x07, 0xff, 0xff, 0xfc, 0x1f, 0xff, 0xff, 0xff, 0x3f, 0xff, 0xff, 0xff, 0x7f, 0xff,
    0xff, 0xff, 0xff, 0xff, 0xff, 0xff, 0xff, 0xff, 0xff, 0xff, 0xff, 0xff, 0xff, 0xff, 0xff, 0xff};
// 'frame_27_delay-0', 32x32px
const unsigned char epd_bitmap_frame_27_delay_0[] = {
    0xff, 0xff, 0xff, 0xff, 0xff, 0xff, 0xff, 0xff, 0xff, 0xff, 0xff, 0xff, 0xff, 0xff, 0xff, 0xff,
    0xff, 0xff, 0xff, 0xff, 0xff, 0x83, 0xf0, 0xff, 0xff, 0x83, 0xf0, 0xff, 0xfe, 0x01, 0xc0, 0x3f,
    0xfe, 0x00, 0xc0, 0x3f, 0xf8, 0x70, 0x00, 0x0f, 0xf8, 0x70, 0x00, 0x0f, 0xe1, 0xf0, 0x00, 0x03,
    0xe1, 0xc0, 0x00, 0x03, 0xe0, 0x00, 0x00, 0x03, 0xe0, 0x00, 0x00, 0x03, 0xf8, 0x00, 0x00, 0x07,
    0xf8, 0x00, 0x00, 0x0f, 0xfe, 0x00, 0x00, 0x3f, 0xfe, 0x00, 0x00, 0x3f, 0xff, 0x80, 0x00, 0xff,
    0xff, 0x80, 0x00, 0xff, 0xff, 0xe0, 0x01, 0xff, 0xff, 0xe0, 0x01, 0xff, 0xff, 0xf0, 0x07, 0xff,
    0xff, 0xfc, 0x1f, 0xff, 0xff, 0xfc, 0x1f, 0xff, 0xff, 0xff, 0x7f, 0xff, 0xff, 0xff, 0x7f, 0xff,
    0xff, 0xff, 0xff, 0xff, 0xff, 0xff, 0xff, 0xff, 0xff, 0xff, 0xff, 0xff, 0xff, 0xff, 0xff, 0xff};
// 'frame_30_delay-0', 32x32px
const unsigned char epd_bitmap_frame_30_delay_0[] = {
    0xff, 0xff, 0xff, 0xff, 0xff, 0xff, 0xff, 0xff, 0xff, 0xff, 0xff, 0xff, 0xff, 0xff, 0xff, 0xff,
    0xff, 0xff, 0xff, 0xff, 0xff, 0x03, 0xf0, 0x7f, 0xff, 0x03, 0xe0, 0x3f, 0xfc, 0x01, 0xc0, 0x1f,
    0xf8, 0x00, 0x00, 0x07, 0xf8, 0x60, 0x00, 0x07, 0xe1, 0xe0, 0x00, 0x01, 0xe1, 0x80, 0x00, 0x01,
    0xe1, 0x80, 0x00, 0x01, 0xe0, 0x00, 0x00, 0x01, 0xe0, 0x00, 0x00, 0x01, 0xf0, 0x00, 0x00, 0x07,
    0xf8, 0x00, 0x00, 0x07, 0xfc, 0x00, 0x00, 0x1f, 0xfc, 0x00, 0x00, 0x1f, 0xff, 0x00, 0x00, 0x7f,
    0xff, 0x00, 0x00, 0x7f, 0xff, 0xc0, 0x01, 0xff, 0xff, 0xc0, 0x01, 0xff, 0xff, 0xf0, 0x07, 0xff,
    0xff, 0xf0, 0x07, 0xff, 0xff, 0xfc, 0x1f, 0xff, 0xff, 0xfc, 0x1f, 0xff, 0xff, 0xff, 0x7f, 0xff,
    0xff, 0xff, 0x7f, 0xff, 0xff, 0xff, 0xff, 0xff, 0xff, 0xff, 0xff, 0xff, 0xff, 0xff, 0xff, 0xff};
// 'frame_33_delay-0', 32x32px
const unsigned char epd_bitmap_frame_33_delay_0[] = {
    0xff, 0xff, 0xff, 0xff, 0xff, 0xff, 0xff, 0xff, 0xff, 0xff, 0xff, 0xff, 0xff, 0xff, 0xff, 0xff,
    0xff, 0x07, 0xf0, 0x7f, 0xff, 0x07, 0xf0, 0x7f, 0xfc, 0x01, 0xc0, 0x1f, 0xfc, 0x01, 0xc0, 0x1f,
    0xf0, 0xe0, 0x00, 0x07, 0xf0, 0xe0, 0x00, 0x07, 0xc3, 0xe0, 0x00, 0x01, 0xc3, 0x80, 0x00, 0x01,
    0xc3, 0x80, 0x00, 0x01, 0xc0, 0x00, 0x00, 0x01, 0xc0, 0x00, 0x00, 0x01, 0xf0, 0x00, 0x00, 0x03,
    0xf0, 0x00, 0x00, 0x07, 0xfc, 0x00, 0x00, 0x0f, 0xfc, 0x00, 0x00, 0x1f, 0xff, 0x00, 0x00, 0x3f,
    0xff, 0x00, 0x00, 0x7f, 0xff, 0xc0, 0x00, 0xff, 0xff, 0xc0, 0x01, 0xff, 0xff, 0xf0, 0x03, 0xff,
    0xff, 0xf0, 0x07, 0xff, 0xff, 0xfc, 0x0f, 0xff, 0xff, 0xfc, 0x1f, 0xff, 0xff, 0xff, 0x3f, 0xff,
    0xff, 0xff, 0x7f, 0xff, 0xff, 0xff, 0xff, 0xff, 0xff, 0xff, 0xff, 0xff, 0xff, 0xff, 0xff, 0xff};
// 'frame_32_delay-0', 32x32px
const unsigned char epd_bitmap_frame_32_delay_0[] = {
    0xff, 0xff, 0xff, 0xff, 0xff, 0xff, 0xff, 0xff, 0xff, 0xff, 0xff, 0xff, 0xff, 0xff, 0xff, 0xff,
    0xff, 0x07, 0xf0, 0x7f, 0xff, 0x07, 0xf0, 0x7f, 0xfc, 0x01, 0xc0, 0x1f, 0xfc, 0x01, 0xc0, 0x1f,
    0xf0, 0xe0, 0x00, 0x07, 0xf0, 0xe0, 0x00, 0x07, 0xc3, 0xe0, 0x00, 0x01, 0xc3, 0x80, 0x00, 0x01,
    0xc3, 0x80, 0x00, 0x01, 0xc0, 0x00, 0x00, 0x01, 0xc0, 0x00, 0x00, 0x01, 0xf0, 0x00, 0x00, 0x07,
    0xf0, 0x00, 0x00, 0x07, 0xfc, 0x00, 0x00, 0x1f, 0xfc, 0x00, 0x00, 0x1f, 0xff, 0x00, 0x00, 0x7f,
    0xff, 0x00, 0x00, 0x7f, 0xff, 0xc0, 0x01, 0xff, 0xff, 0xc0, 0x01, 0xff, 0xff, 0xf0, 0x07, 0xff,
    0xff, 0xf0, 0x07, 0xff, 0xff, 0xfc, 0x1f, 0xff, 0xff, 0xfc, 0x1f, 0xff, 0xff, 0xff, 0x7f, 0xff,
    0xff, 0xff, 0x7f, 0xff, 0xff, 0xff, 0xff, 0xff, 0xff, 0xff, 0xff, 0xff, 0xff, 0xff, 0xff, 0xff};
// 'frame_38_delay-0', 32x32px
const unsigned char epd_bitmap_frame_38_delay_0[] = {
    0xff, 0xff, 0xff, 0xff, 0xff, 0xff, 0xff, 0xff, 0xff, 0xff, 0xff, 0xff, 0xff, 0xff, 0xff, 0xff,
    0xff, 0xff, 0xff, 0xff, 0xff, 0x03, 0xf0, 0x7f, 0xff, 0x03, 0xe0, 0x7f, 0xfe, 0x01, 0xc0, 0x1f,
    0xf8, 0x00, 0x00, 0x0f, 0xf8, 0x60, 0x00, 0x07, 0xe0, 0x60, 0x00, 0x03, 0xe1, 0x80, 0x00, 0x03,
    0xe1, 0x80, 0x00, 0x03, 0xe0, 0x00, 0x00, 0x03, 0xe0, 0x00, 0x00, 0x03, 0xf0, 0x00, 0x00, 0x07,
    0xf8, 0x00, 0x00, 0x07, 0xfc, 0x00, 0x00, 0x1f, 0xfe, 0x00, 0x00, 0x1f, 0xff, 0x00, 0x00, 0x7f,
    0xff, 0x00, 0x00, 0x7f, 0xff, 0xc0, 0x01, 0xff, 0xff, 0xc0, 0x01, 0xff, 0xff, 0xf0, 0x07, 0xff,
    0xff, 0xf0, 0x07, 0xff, 0xff, 0xfc, 0x1f, 0xff, 0xff, 0xfc, 0x1f, 0xff, 0xff, 0xff, 0x7f, 0xff,
    0xff, 0xff, 0x7f, 0xff, 0xff, 0xff, 0xff, 0xff, 0xff, 0xff, 0xff, 0xff, 0xff, 0xff, 0xff, 0xff};
// 'frame_35_delay-0', 32x32px
const unsigned char epd_bitmap_frame_35_delay_0[] = {
    0xff, 0xff, 0xff, 0xff, 0xff, 0xff, 0xff, 0xff, 0xff, 0xff, 0xff, 0xff, 0xff, 0xff, 0xff, 0xff,
    0xff, 0x07, 0xf0, 0x7f, 0xff, 0x07, 0xf0, 0x7f, 0xfc, 0x01, 0xc0, 0x1f, 0xfc, 0x01, 0xc0, 0x1f,
    0xf0, 0xe0, 0x00, 0x07, 0xf0, 0xe0, 0x00, 0x07, 0xc3, 0xe0, 0x00, 0x01, 0xc3, 0x80, 0x00, 0x01,
    0xc3, 0x80, 0x00, 0x01, 0xc0, 0x00, 0x00, 0x01, 0xc0, 0x00, 0x00, 0x01, 0xf0, 0x00, 0x00, 0x03,
    0xf0, 0x00, 0x00, 0x07, 0xfc, 0x00, 0x00, 0x0f, 0xfc, 0x00, 0x00, 0x1f, 0xff, 0x00, 0x00, 0x3f,
    0xff, 0x00, 0x00, 0x7f, 0xff, 0xc0, 0x00, 0xff, 0xff, 0xc0, 0x01, 0xff, 0xff, 0xf0, 0x07, 0xff,
    0xff, 0xf0, 0x07, 0xff, 0xff, 0xfc, 0x1f, 0xff, 0xff, 0xfc, 0x1f, 0xff, 0xff, 0xff, 0x7f, 0xff,
    0xff, 0xff, 0x7f, 0xff, 0xff, 0xff, 0xff, 0xff, 0xff, 0xff, 0xff, 0xff, 0xff, 0xff, 0xff, 0xff};
// 'frame_36_delay-0', 32x32px
const unsigned char epd_bitmap_frame_36_delay_0[] = {
    0xff, 0xff, 0xff, 0xff, 0xff, 0xff, 0xff, 0xff, 0xff, 0xff, 0xff, 0xff, 0xff, 0xff, 0xff, 0xff,
    0xff, 0x07, 0xf0, 0x7f, 0xff, 0x07, 0xf0, 0x7f, 0xfc, 0x01, 0xc0, 0x1f, 0xfc, 0x01, 0xc0, 0x1f,
    0xf0, 0xe0, 0x00, 0x07, 0xf0, 0xe0, 0x00, 0x07, 0xc3, 0xe0, 0x00, 0x01, 0xc3, 0x80, 0x00, 0x01,
    0xc3, 0x80, 0x00, 0x01, 0xc0, 0x00, 0x00, 0x01, 0xc0, 0x00, 0x00, 0x01, 0xf0, 0x00, 0x00, 0x07,
    0xf0, 0x00, 0x00, 0x07, 0xfc, 0x00, 0x00, 0x1f, 0xfc, 0x00, 0x00, 0x1f, 0xff, 0x00, 0x00, 0x7f,
    0xff, 0x00, 0x00, 0x7f, 0xff, 0xc0, 0x01, 0xff, 0xff, 0xc0, 0x01, 0xff, 0xff, 0xf0, 0x07, 0xff,
    0xff, 0xf0, 0x07, 0xff, 0xff, 0xfc, 0x1f, 0xff, 0xff, 0xfc, 0x1f, 0xff, 0xff, 0xff, 0x7f, 0xff,
    0xff, 0xff, 0x7f, 0xff, 0xff, 0xff, 0xff, 0xff, 0xff, 0xff, 0xff, 0xff, 0xff, 0xff, 0xff, 0xff};
// 'frame_37_delay-0', 32x32px
const unsigned char epd_bitmap_frame_37_delay_0[] = {
    0xff, 0xff, 0xff, 0xff, 0xff, 0xff, 0xff, 0xff, 0xff, 0xff, 0xff, 0xff, 0xff, 0xff, 0xff, 0xff,
    0xff, 0x07, 0xf0, 0x7f, 0xff, 0x07, 0xf0, 0x7f, 0xfc, 0x01, 0xc0, 0x1f, 0xfc, 0x01, 0xc0, 0x1f,
    0xf0, 0x60, 0x00, 0x07, 0xf0, 0xe0, 0x00, 0x07, 0xc1, 0xe0, 0x00, 0x01, 0xc3, 0x80, 0x00, 0x01,
    0xc3, 0x80, 0x00, 0x01, 0xc0, 0x00, 0x00, 0x01, 0xc0, 0x00, 0x00, 0x01, 0xf0, 0x00, 0x00, 0x07,
    0xf0, 0x00, 0x00, 0x07, 0xfc, 0x00, 0x00, 0x1f, 0xfc, 0x00, 0x00, 0x1f, 0xff, 0x00, 0x00, 0x7f,
    0xff, 0x00, 0x00, 0x7f, 0xff, 0xc0, 0x01, 0xff, 0xff, 0xc0, 0x01, 0xff, 0xff, 0xf0, 0x07, 0xff,
    0xff, 0xf0, 0x07, 0xff, 0xff, 0xfc, 0x1f, 0xff, 0xff, 0xfc, 0x1f, 0xff, 0xff, 0xff, 0x7f, 0xff,
    0xff, 0xff, 0x7f, 0xff, 0xff, 0xff, 0xff, 0xff, 0xff, 0xff, 0xff, 0xff, 0xff, 0xff, 0xff, 0xff};
// 'frame_39_delay-0', 32x32px
const unsigned char epd_bitmap_frame_39_delay_0[] = {
    0xff, 0xff, 0xff, 0xff, 0xff, 0xff, 0xff, 0xff, 0xff, 0xff, 0xff, 0xff, 0xff, 0xff, 0xff, 0xff,
    0xff, 0xff, 0xff, 0xff, 0xff, 0x83, 0xf0, 0x7f, 0xff, 0x03, 0xf0, 0x7f, 0xfe, 0x01, 0xc0, 0x3f,
    0xfe, 0x00, 0xc0, 0x1f, 0xf8, 0x60, 0x00, 0x0f, 0xf0, 0x60, 0x00, 0x07, 0xe1, 0xe0, 0x00, 0x03,
    0xe1, 0xc0, 0x00, 0x03, 0xe0, 0x00, 0x00, 0x03, 0xe0, 0x00, 0x00, 0x03, 0xf0, 0x00, 0x00, 0x07,
    0xf8, 0x00, 0x00, 0x0f, 0xfe, 0x00, 0x00, 0x1f, 0xfe, 0x00, 0x00, 0x3f, 0xff, 0x80, 0x00, 0x7f,
    0xff, 0x80, 0x00, 0x7f, 0xff, 0xc0, 0x01, 0xff, 0xff, 0xc0, 0x01, 0xff, 0xff, 0xf0, 0x07, 0xff,
    0xff, 0xf0, 0x07, 0xff, 0xff, 0xfc, 0x1f, 0xff, 0xff, 0xfc, 0x1f, 0xff, 0xff, 0xff, 0x7f, 0xff,
    0xff, 0xff, 0xff, 0xff, 0xff, 0xff, 0xff, 0xff, 0xff, 0xff, 0xff, 0xff, 0xff, 0xff, 0xff, 0xff};
// 'frame_43_delay-0', 32x32px
const unsigned char epd_bitmap_frame_43_delay_0[] = {
    0xff, 0xff, 0xff, 0xff, 0xff, 0xff, 0xff, 0xff, 0xff, 0xff, 0xff, 0xff, 0xff, 0xff, 0xff, 0xff,
    0xff, 0xff, 0xff, 0xff, 0xff, 0xff, 0xff, 0xff, 0xff, 0x83, 0xe0, 0xff, 0xff, 0x83, 0xe0, 0xff,
    0xff, 0x01, 0xc0, 0x3f, 0xfc, 0x30, 0x00, 0x1f, 0xfc, 0x70, 0x00, 0x1f, 0xf0, 0xf0, 0x00, 0x07,
    0xf0, 0xc0, 0x00, 0x07, 0xf0, 0xc0, 0x00, 0x07, 0xf0, 0x00, 0x00, 0x07, 0xf0, 0x00, 0x00, 0x07,
    0xfc, 0x00, 0x00, 0x1f, 0xfe, 0x00, 0x00, 0x3f, 0xff, 0x00, 0x00, 0x3f, 0xff, 0x80, 0x00, 0xff,
    0xff, 0x80, 0x00, 0xff, 0xff, 0xe0, 0x03, 0xff, 0xff, 0xf0, 0x07, 0xff, 0xff, 0xf8, 0x07, 0xff,
    0xff, 0xfc, 0x1f, 0xff, 0xff, 0xfc, 0x1f, 0xff, 0xff, 0xff, 0x7f, 0xff, 0xff, 0xff, 0xff, 0xff,
    0xff, 0xff, 0xff, 0xff, 0xff, 0xff, 0xff, 0xff, 0xff, 0xff, 0xff, 0xff, 0xff, 0xff, 0xff, 0xff};
// 'frame_41_delay-0', 32x32px
const unsigned char epd_bitmap_frame_41_delay_0[] = {
    0xff, 0xff, 0xff, 0xff, 0xff, 0xff, 0xff, 0xff, 0xff, 0xff, 0xff, 0xff, 0xff, 0xff, 0xff, 0xff,
    0xff, 0xff, 0xff, 0xff, 0xff, 0x83, 0xf0, 0xff, 0xff, 0x83, 0xf0, 0xff, 0xfe, 0x01, 0xc0, 0x3f,
    0xfe, 0x00, 0xc0, 0x3f, 0xf8, 0x70, 0x00, 0x0f, 0xf8, 0x70, 0x00, 0x0f, 0xf1, 0xf0, 0x00, 0x03,
    0xf1, 0xc0, 0x00, 0x03, 0xf0, 0xc0, 0x00, 0x03, 0xf0, 0x00, 0x00, 0x03, 0xf0, 0x00, 0x00, 0x07,
    0xf8, 0x00, 0x00, 0x0f, 0xfe, 0x00, 0x00, 0x3f, 0xfe, 0x00, 0x00, 0x3f, 0xff, 0x80, 0x00, 0xff,
    0xff, 0x80, 0x00, 0xff, 0xff, 0xe0, 0x01, 0xff, 0xff, 0xe0, 0x03, 0xff, 0xff, 0xf0, 0x07, 0xff,
    0xff, 0xfc, 0x1f, 0xff, 0xff, 0xfc, 0x1f, 0xff, 0xff, 0xff, 0x7f, 0xff, 0xff, 0xff, 0x7f, 0xff,
    0xff, 0xff, 0xff, 0xff, 0xff, 0xff, 0xff, 0xff, 0xff, 0xff, 0xff, 0xff, 0xff, 0xff, 0xff, 0xff};
// 'frame_42_delay-0', 32x32px
const unsigned char epd_bitmap_frame_42_delay_0[] = {
    0xff, 0xff, 0xff, 0xff, 0xff, 0xff, 0xff, 0xff, 0xff, 0xff, 0xff, 0xff, 0xff, 0xff, 0xff, 0xff,
    0xff, 0xff, 0xff, 0xff, 0xff, 0xff, 0xff, 0xff, 0xff, 0x83, 0xe0, 0xff, 0xff, 0x01, 0xc0, 0x3f,
    0xfe, 0x00, 0xc0, 0x3f, 0xfc, 0x70, 0x00, 0x0f, 0xfc, 0x70, 0x00, 0x0f, 0xf1, 0xf0, 0x00, 0x07,
    0xf1, 0xc0, 0x00, 0x07, 0xf0, 0xc0, 0x00, 0x07, 0xf0, 0x00, 0x00, 0x07, 0xf0, 0x00, 0x00, 0x07,
    0xfc, 0x00, 0x00, 0x0f, 0xfe, 0x00, 0x00, 0x3f, 0xfe, 0x00, 0x00, 0x3f, 0xff, 0x80, 0x00, 0xff,
    0xff, 0x80, 0x00, 0xff, 0xff, 0xe0, 0x03, 0xff, 0xff, 0xf0, 0x07, 0xff, 0xff, 0xf8, 0x07, 0xff,
    0xff, 0xfc, 0x1f, 0xff, 0xff, 0xfc, 0x1f, 0xff, 0xff, 0xff, 0x7f, 0xff, 0xff, 0xff, 0x7f, 0xff,
    0xff, 0xff, 0xff, 0xff, 0xff, 0xff, 0xff, 0xff, 0xff, 0xff, 0xff, 0xff, 0xff, 0xff, 0xff, 0xff};
// 'frame_44_delay-0', 32x32px
const unsigned char epd_bitmap_frame_44_delay_0[] = {
    0xff, 0xff, 0xff, 0xff, 0xff, 0xff, 0xff, 0xff, 0xff, 0xff, 0xff, 0xff, 0xff, 0xff, 0xff, 0xff,
    0xff, 0xff, 0xff, 0xff, 0xff, 0xff, 0xff, 0xff, 0xff, 0x83, 0xe0, 0xff, 0xff, 0x83, 0xe0, 0xff,
    0xff, 0x00, 0xc0, 0x7f, 0xfe, 0x00, 0x80, 0x3f, 0xfc, 0x70, 0x00, 0x1f, 0xf0, 0xf0, 0x00, 0x07,
    0xf0, 0xc0, 0x00, 0x07, 0xf0, 0xc0, 0x00, 0x07, 0xf0, 0x00, 0x00, 0x07, 0xf8, 0x00, 0x00, 0x07,
    0xfc, 0x00, 0x00, 0x1f, 0xff, 0x00, 0x00, 0x3f, 0xff, 0x00, 0x00, 0x7f, 0xff, 0x80, 0x00, 0xff,
    0xff, 0xc0, 0x01, 0xff, 0xff, 0xe0, 0x03, 0xff, 0xff, 0xf8, 0x07, 0xff, 0xff, 0xf8, 0x0f, 0xff,
    0xff, 0xfc, 0x1f, 0xff, 0xff, 0xff, 0x3f, 0xff, 0xff, 0xff, 0x7f, 0xff, 0xff, 0xff, 0xff, 0xff,
    0xff, 0xff, 0xff, 0xff, 0xff, 0xff, 0xff, 0xff, 0xff, 0xff, 0xff, 0xff, 0xff, 0xff, 0xff, 0xff};
// 'frame_21_delay-0', 32x32px
const unsigned char epd_bitmap_frame_21_delay_0[] = {
    0xff, 0xff, 0xff, 0xff, 0xff, 0xff, 0xff, 0xff, 0xff, 0xff, 0xff, 0xff, 0xff, 0xff, 0xff, 0xff,
    0xff, 0x07, 0xf0, 0x7f, 0xff, 0x07, 0xf0, 0x7f, 0xfc, 0x01, 0xc0, 0x1f, 0xfc, 0x01, 0xc0, 0x1f,
    0xf0, 0xe0, 0x00, 0x07, 0xf0, 0xe0, 0x00, 0x07, 0xc3, 0xe0, 0x00, 0x01, 0xc3, 0x80, 0x00, 0x01,
    0xc3, 0x80, 0x00, 0x01, 0xc0, 0x00, 0x00, 0x01, 0xc0, 0x00, 0x00, 0x01, 0xf0, 0x00, 0x00, 0x07,
    0xf0, 0x00, 0x00, 0x07, 0xfc, 0x00, 0x00, 0x1f, 0xfc, 0x00, 0x00, 0x1f, 0xff, 0x00, 0x00, 0x7f,
    0xff, 0x00, 0x00, 0x7f, 0xff, 0xc0, 0x01, 0xff, 0xff, 0xc0, 0x01, 0xff, 0xff, 0xf0, 0x07, 0xff,
    0xff, 0xf0, 0x07, 0xff, 0xff, 0xfc, 0x1f, 0xff, 0xff, 0xfc, 0x1f, 0xff, 0xff, 0xff, 0x7f, 0xff,
    0xff, 0xff, 0x7f, 0xff, 0xff, 0xff, 0xff, 0xff, 0xff, 0xff, 0xff, 0xff, 0xff, 0xff, 0xff, 0xff};
// 'frame_34_delay-0', 32x32px
const unsigned char epd_bitmap_frame_34_delay_0[] = {
    0xff, 0xff, 0xff, 0xff, 0xff, 0xff, 0xff, 0xff, 0xff, 0xff, 0xff, 0xff, 0xff, 0xff, 0xff, 0xff,
    0xff, 0x07, 0xf0, 0x7f, 0xff, 0x03, 0xf0, 0x3f, 0xfc, 0x01, 0xc0, 0x0f, 0xfc, 0x00, 0xc0, 0x0f,
    0xf0, 0xe0, 0x00, 0x03, 0xf0, 0xe0, 0x00, 0x03, 0xc3, 0xe0, 0x00, 0x00, 0xc3, 0x80, 0x00, 0x00,
    0xc3, 0x80, 0x00, 0x00, 0xc0, 0x00, 0x00, 0x00, 0xc0, 0x00, 0x00, 0x00, 0xe0, 0x00, 0x00, 0x03,
    0xf0, 0x00, 0x00, 0x03, 0xf8, 0x00, 0x00, 0x0f, 0xfc, 0x00, 0x00, 0x0f, 0xfe, 0x00, 0x00, 0x3f,
    0xff, 0x00, 0x00, 0x7f, 0xff, 0x80, 0x00, 0xff, 0xff, 0xc0, 0x01, 0xff, 0xff, 0xc0, 0x01, 0xff,
    0xff, 0xf0, 0x07, 0xff, 0xff, 0xf0, 0x07, 0xff, 0xff, 0xfc, 0x1f, 0xff, 0xff, 0xfc, 0x1f, 0xff,
    0xff, 0xff, 0x7f, 0xff, 0xff, 0xff, 0x7f, 0xff, 0xff, 0xff, 0xff, 0xff, 0xff, 0xff, 0xff, 0xff};
// 'frame_40_delay-0', 32x32px
const unsigned char epd_bitmap_frame_40_delay_0[] = {
    0xff, 0xff, 0xff, 0xff, 0xff, 0xff, 0xff, 0xff, 0xff, 0xff, 0xff, 0xff, 0xff, 0xff, 0xff, 0xff,
    0xff, 0xff, 0xff, 0xff, 0xff, 0x83, 0xf0, 0xff, 0xff, 0x83, 0xf0, 0x7f, 0xfe, 0x01, 0xc0, 0x3f,
    0xfe, 0x00, 0xc0, 0x3f, 0xf8, 0x70, 0x00, 0x0f, 0xf8, 0x70, 0x00, 0x0f, 0xe1, 0xe0, 0x00, 0x03,
    0xe1, 0xc0, 0x00, 0x03, 0xe0, 0x00, 0x00, 0x03, 0xe0, 0x00, 0x00, 0x03, 0xf0, 0x00, 0x00, 0x03,
    0xf8, 0x00, 0x00, 0x0f, 0xfe, 0x00, 0x00, 0x3f, 0xfe, 0x00, 0x00, 0x3f, 0xff, 0x80, 0x00, 0x7f,
    0xff, 0x80, 0x00, 0xff, 0xff, 0xe0, 0x01, 0xff, 0xff, 0xe0, 0x01, 0xff, 0xff, 0xf0, 0x07, 0xff,
    0xff, 0xf8, 0x07, 0xff, 0xff, 0xfc, 0x1f, 0xff, 0xff, 0xff, 0x7f, 0xff, 0xff, 0xff, 0x7f, 0xff,
    0xff, 0xff, 0xff, 0xff, 0xff, 0xff, 0xff, 0xff, 0xff, 0xff, 0xff, 0xff, 0xff, 0xff, 0xff, 0xff};
// 'frame_26_delay-0', 32x32px
const unsigned char epd_bitmap_frame_26_delay_0[] = {
    0xff, 0xff, 0xff, 0xff, 0xff, 0xff, 0xff, 0xff, 0xff, 0xff, 0xff, 0xff, 0xff, 0xff, 0xff, 0xff,
    0xff, 0xff, 0xff, 0xff, 0xff, 0x83, 0xf0, 0x7f, 0xff, 0x83, 0xf0, 0x7f, 0xfe, 0x01, 0xc0, 0x3f,
    0xfe, 0x00, 0xc0, 0x3f, 0xf8, 0x70, 0x00, 0x0f, 0xf8, 0x70, 0x00, 0x07, 0xe1, 0xe0, 0x00, 0x03,
    0xe1, 0xc0, 0x00, 0x03, 0xe0, 0x00, 0x00, 0x03, 0xe0, 0x00, 0x00, 0x03, 0xe0, 0x00, 0x00, 0x03,
    0xf8, 0x00, 0x00, 0x0f, 0xfe, 0x00, 0x00, 0x1f, 0xfe, 0x00, 0x00, 0x3f, 0xff, 0x80, 0x00, 0x7f,
    0xff, 0x80, 0x00, 0x7f, 0xff, 0xe0, 0x01, 0xff, 0xff, 0xe0, 0x01, 0xff, 0xff, 0xf0, 0x07, 0xff,
    0xff, 0xf0, 0x07, 0xff, 0xff, 0xfc, 0x1f, 0xff, 0xff, 0xff, 0x3f, 0xff, 0xff, 0xff, 0x7f, 0xff,
    0xff, 0xff, 0xff, 0xff, 0xff, 0xff, 0xff, 0xff, 0xff, 0xff, 0xff, 0xff, 0xff, 0xff, 0xff, 0xff};
// 'frame_31_delay-0', 32x32px
const unsigned char epd_bitmap_frame_31_delay_0[] = {
    0xff, 0xff, 0xff, 0xff, 0xff, 0xff, 0xff, 0xff, 0xff, 0xff, 0xff, 0xff, 0xff, 0xff, 0xff, 0xff,
    0xff, 0x07, 0xf0, 0x7f, 0xff, 0x07, 0xf0, 0x7f, 0xfc, 0x01, 0xc0, 0x1f, 0xfc, 0x01, 0xc0, 0x1f,
    0xf0, 0x60, 0x00, 0x07, 0xf0, 0xe0, 0x00, 0x07, 0xc1, 0xe0, 0x00, 0x01, 0xc3, 0x80, 0x00, 0x01,
    0xc3, 0x80, 0x00, 0x01, 0xc0, 0x00, 0x00, 0x01, 0xc0, 0x00, 0x00, 0x01, 0xf0, 0x00, 0x00, 0x07,
    0xf0, 0x00, 0x00, 0x07, 0xfc, 0x00, 0x00, 0x1f, 0xfc, 0x00, 0x00, 0x1f, 0xff, 0x00, 0x00, 0x7f,
    0xff, 0x00, 0x00, 0x7f, 0xff, 0xc0, 0x01, 0xff, 0xff, 0xc0, 0x01, 0xff, 0xff, 0xf0, 0x07, 0xff,
    0xff, 0xf0, 0x07, 0xff, 0xff, 0xfc, 0x1f, 0xff, 0xff, 0xfc, 0x1f, 0xff, 0xff, 0xff, 0x7f, 0xff,
    0xff, 0xff, 0x7f, 0xff, 0xff, 0xff, 0xff, 0xff, 0xff, 0xff, 0xff, 0xff, 0xff, 0xff, 0xff, 0xff};
// 'frame_29_delay-0', 32x32px
const unsigned char epd_bitmap_frame_29_delay_0[] = {
    0xff, 0xff, 0xff, 0xff, 0xff, 0xff, 0xff, 0xff, 0xff, 0xff, 0xff, 0xff, 0xff, 0xff, 0xff, 0xff,
    0xff, 0xff, 0xff, 0xff, 0xff, 0x83, 0xf0, 0x7f, 0xff, 0x03, 0xe0, 0x7f, 0xfe, 0x01, 0xc0, 0x1f,
    0xfc, 0x00, 0x80, 0x1f, 0xf8, 0x60, 0x00, 0x0f, 0xe0, 0x60, 0x00, 0x03, 0xe1, 0xc0, 0x00, 0x03,
    0xe1, 0xc0, 0x00, 0x03, 0xe0, 0x00, 0x00, 0x03, 0xe0, 0x00, 0x00, 0x03, 0xf0, 0x00, 0x00, 0x07,
    0xf8, 0x00, 0x00, 0x0f, 0xfc, 0x00, 0x00, 0x1f, 0xfe, 0x00, 0x00, 0x1f, 0xff, 0x00, 0x00, 0x7f,
    0xff, 0x80, 0x00, 0x7f, 0xff, 0xc0, 0x01, 0xff, 0xff, 0xc0, 0x01, 0xff, 0xff, 0xf0, 0x07, 0xff,
    0xff, 0xf0, 0x07, 0xff, 0xff, 0xfc, 0x1f, 0xff, 0xff, 0xfc, 0x1f, 0xff, 0xff, 0xff, 0x7f, 0xff,
    0xff, 0xff, 0xff, 0xff, 0xff, 0xff, 0xff, 0xff, 0xff, 0xff, 0xff, 0xff, 0xff, 0xff, 0xff, 0xff};

// Array of all bitmaps for convenience. (Total bytes used to store images in  = 6480)
const int epd_bitmap_allArray_LEN = 45;
const unsigned char *epd_bitmap_allArray[45] = {
    epd_bitmap_frame_00_delay_0,
    //	epd_bitmap_frame_01_delay_0,
    //	epd_bitmap_frame_02_delay_0,
    //	epd_bitmap_frame_03_delay_0,
    epd_bitmap_frame_04_delay_0,
    //	epd_bitmap_frame_05_delay_0,
    //	epd_bitmap_frame_06_delay_0,
    //	epd_bitmap_frame_07_delay_0,
    //	epd_bitmap_frame_08_delay_0,
    //	epd_bitmap_frame_09_delay_0,
    epd_bitmap_frame_10_delay_0,
    //	epd_bitmap_frame_11_delay_0,
    //	epd_bitmap_frame_12_delay_0,
    //	epd_bitmap_frame_13_delay_0,
    //	epd_bitmap_frame_14_delay_0,
    //	epd_bitmap_frame_15_delay_0,
    epd_bitmap_frame_16_delay_0,
    //	epd_bitmap_frame_17_delay_0,
    //	epd_bitmap_frame_18_delay_0,
    //	epd_bitmap_frame_19_delay_0,
    //	epd_bitmap_frame_20_delay_0,
    //	epd_bitmap_frame_21_delay_0,
    //	epd_bitmap_frame_22_delay_0,
    //	epd_bitmap_frame_23_delay_0,
    //	epd_bitmap_frame_24_delay_0,
    //	epd_bitmap_frame_25_delay_0,
    //	epd_bitmap_frame_26_delay_0,
    //	epd_bitmap_frame_27_delay_0,
    //	epd_bitmap_frame_28_delay_0,
    //	epd_bitmap_frame_29_delay_0,
    //	epd_bitmap_frame_30_delay_0,
    //	epd_bitmap_frame_31_delay_0,
    //	epd_bitmap_frame_32_delay_0,
    //	epd_bitmap_frame_33_delay_0,
    //	epd_bitmap_frame_34_delay_0,
    //	epd_bitmap_frame_35_delay_0,
    //	epd_bitmap_frame_36_delay_0,
    //	epd_bitmap_frame_37_delay_0,
    //	epd_bitmap_frame_38_delay_0,
    //	epd_bitmap_frame_39_delay_0,
    //	epd_bitmap_frame_40_delay_0,
    //	epd_bitmap_frame_41_delay_0,
    //	epd_bitmap_frame_42_delay_0,
    //	epd_bitmap_frame_43_delay_0,
    //	epd_bitmap_frame_44_delay_0
};

/* USER CODE END Includes */

I2C_HandleTypeDef hi2c1;

UART_HandleTypeDef huart2;

void SystemClock_Config(void);
static void MX_GPIO_Init(void);
static void MX_USART2_UART_Init(void);
static void MX_I2C1_Init(void);

void init_oled(void);
void init_sensor(void);
void update_oled(uint8_t x, uint8_t y, char *str);

int main(void)
{

    /* MCU Configuration--------------------------------------------------------*/

    /* Reset of all peripherals, Initializes the Flash interface and the Systick. */
    HAL_Init();

    /* Configure the system clock */
    SystemClock_Config();

    /* Initialize all configured peripherals */
    MX_GPIO_Init();
    MX_USART2_UART_Init();
    MX_I2C1_Init();

    init_oled();
    init_sensor();

    ssd1306_Fill(Black);    // Clear screen
    ssd1306_UpdateScreen(); // Refresh display

    /* Infinite loop */
    /* USER CODE BEGIN WHILE */
    while (1)
    {

        char uart_buffer[50];
        float spo2 = MAX30100_CalculateSpO2();

        //	MAX30100_PlotTemperatureToUART(&huart2);
        HAL_GPIO_TogglePin(GPIOB, GPIO_PIN_6);

        snprintf(uart_buffer, sizeof(uart_buffer), "SpO2: %.3f\r\n", spo2);
        update_oled(0, 0, uart_buffer);

        HAL_Delay(100);
    }
    /* USER CODE END 3 */
}

void init_sensor(void)
{
    MAX30100_Init(&hi2c1, &huart2);
    MAX30100_SetSpO2SampleRate(MAX30100_SPO2SR_50);
    MAX30100_SetLEDPulseWidth(MAX30100_LEDPW_1600);
    MAX30100_SetLEDCurrent(MAX30100_LEDCURRENT_DEFAULT, MAX30100_LEDCURRENT_DEFAULT);
    MAX30100_SetMode(MAX30100_SPO2_MODE);
}

void init_oled(void)
{
    ssd1306_Init();
    ssd1306_Fill(Black); // Clear screen
    ssd1306_SetCursor(10, 5);
    ssd1306_WriteString("MAX30100 Ready", Font_7x10, White);
    ssd1306_UpdateScreen(); // Refresh display
    HAL_Delay(4000);
}

void update_oled(uint8_t x, uint8_t y, char *str)
{
    ssd1306_SetCursor(x, y);
    ssd1306_WriteString(str, Font_7x10, White);

    ssd1306_DrawBitmap(45, 26, epd_bitmap_frame_10_delay_0, 32, 32, White);

    ssd1306_UpdateScreen();
}

void SystemClock_Config(void)
{
    RCC_OscInitTypeDef RCC_OscInitStruct = {0};
    RCC_ClkInitTypeDef RCC_ClkInitStruct = {0};

    /** Configure the main internal regulator output voltage
     */
    HAL_PWREx_ControlVoltageScaling(PWR_REGULATOR_VOLTAGE_SCALE1);

    /** Initializes the RCC Oscillators according to the specified parameters
     * in the RCC_OscInitTypeDef structure.
     */
    RCC_OscInitStruct.OscillatorType = RCC_OSCILLATORTYPE_HSI;
    RCC_OscInitStruct.HSIState = RCC_HSI_ON;
    RCC_OscInitStruct.HSIDiv = RCC_HSI_DIV1;
    RCC_OscInitStruct.HSICalibrationValue = RCC_HSICALIBRATION_DEFAULT;
    RCC_OscInitStruct.PLL.PLLState = RCC_PLL_NONE;
    if (HAL_RCC_OscConfig(&RCC_OscInitStruct) != HAL_OK)
    {
        Error_Handler();
    }

    /** Initializes the CPU, AHB and APB buses clocks
     */
    RCC_ClkInitStruct.ClockType = RCC_CLOCKTYPE_HCLK | RCC_CLOCKTYPE_SYSCLK | RCC_CLOCKTYPE_PCLK1;
    RCC_ClkInitStruct.SYSCLKSource = RCC_SYSCLKSOURCE_HSI;
    RCC_ClkInitStruct.AHBCLKDivider = RCC_SYSCLK_DIV1;
    RCC_ClkInitStruct.APB1CLKDivider = RCC_HCLK_DIV1;

    if (HAL_RCC_ClockConfig(&RCC_ClkInitStruct, FLASH_LATENCY_0) != HAL_OK)
    {
        Error_Handler();
    }
}

static void MX_I2C1_Init(void)
{

    hi2c1.Instance = I2C1;
    hi2c1.Init.Timing = 0x00503D58;
    hi2c1.Init.OwnAddress1 = 0;
    hi2c1.Init.AddressingMode = I2C_ADDRESSINGMODE_7BIT;
    hi2c1.Init.DualAddressMode = I2C_DUALADDRESS_DISABLE;
    hi2c1.Init.OwnAddress2 = 0;
    hi2c1.Init.OwnAddress2Masks = I2C_OA2_NOMASK;
    hi2c1.Init.GeneralCallMode = I2C_GENERALCALL_DISABLE;
    hi2c1.Init.NoStretchMode = I2C_NOSTRETCH_DISABLE;
    if (HAL_I2C_Init(&hi2c1) != HAL_OK)
    {
        Error_Handler();
    }

    /** Configure Analogue filter
     */
    if (HAL_I2CEx_ConfigAnalogFilter(&hi2c1, I2C_ANALOGFILTER_ENABLE) != HAL_OK)
    {
        Error_Handler();
    }

    /** Configure Digital filter
     */
    if (HAL_I2CEx_ConfigDigitalFilter(&hi2c1, 0) != HAL_OK)
    {
        Error_Handler();
    }
}

static void MX_USART2_UART_Init(void)
{

    huart2.Instance = USART2;
    huart2.Init.BaudRate = 115200;
    huart2.Init.WordLength = UART_WORDLENGTH_8B;
    huart2.Init.StopBits = UART_STOPBITS_1;
    huart2.Init.Parity = UART_PARITY_NONE;
    huart2.Init.Mode = UART_MODE_TX_RX;
    huart2.Init.HwFlowCtl = UART_HWCONTROL_NONE;
    huart2.Init.OverSampling = UART_OVERSAMPLING_16;
    huart2.Init.OneBitSampling = UART_ONE_BIT_SAMPLE_DISABLE;
    huart2.Init.ClockPrescaler = UART_PRESCALER_DIV1;
    huart2.AdvancedInit.AdvFeatureInit = UART_ADVFEATURE_NO_INIT;
    if (HAL_UART_Init(&huart2) != HAL_OK)
    {
        Error_Handler();
    }
}

static void MX_GPIO_Init(void)
{
    GPIO_InitTypeDef GPIO_InitStruct = {0};

    /* GPIO Ports Clock Enable */
    __HAL_RCC_GPIOC_CLK_ENABLE();
    __HAL_RCC_GPIOF_CLK_ENABLE();
    __HAL_RCC_GPIOA_CLK_ENABLE();
    __HAL_RCC_GPIOB_CLK_ENABLE();

    /*Configure GPIO pin Output Level */
    HAL_GPIO_WritePin(LD3_GPIO_Port, LD3_Pin, GPIO_PIN_RESET);

    /*Configure GPIO pin Output Level */
    HAL_GPIO_WritePin(GPIOB, GPIO_PIN_6, GPIO_PIN_RESET);

    /*Configure GPIO pin : T_NRST_Pin */
    GPIO_InitStruct.Pin = T_NRST_Pin;
    GPIO_InitStruct.Mode = GPIO_MODE_IT_RISING;
    GPIO_InitStruct.Pull = GPIO_NOPULL;
    HAL_GPIO_Init(T_NRST_GPIO_Port, &GPIO_InitStruct);

    /*Configure GPIO pin : Int__Pin */
    GPIO_InitStruct.Pin = Int__Pin;
    GPIO_InitStruct.Mode = GPIO_MODE_IT_FALLING;
    GPIO_InitStruct.Pull = GPIO_PULLUP;
    HAL_GPIO_Init(Int__GPIO_Port, &GPIO_InitStruct);

    /*Configure GPIO pin : LD3_Pin */
    GPIO_InitStruct.Pin = LD3_Pin;
    GPIO_InitStruct.Mode = GPIO_MODE_OUTPUT_PP;
    GPIO_InitStruct.Pull = GPIO_NOPULL;
    GPIO_InitStruct.Speed = GPIO_SPEED_FREQ_LOW;
    HAL_GPIO_Init(LD3_GPIO_Port, &GPIO_InitStruct);

    /*Configure GPIO pin : PB6 */
    GPIO_InitStruct.Pin = GPIO_PIN_6;
    GPIO_InitStruct.Mode = GPIO_MODE_OUTPUT_PP;
    GPIO_InitStruct.Pull = GPIO_NOPULL;
    GPIO_InitStruct.Speed = GPIO_SPEED_FREQ_LOW;
    HAL_GPIO_Init(GPIOB, &GPIO_InitStruct);

    /* EXTI interrupt init*/
    HAL_NVIC_SetPriority(EXTI0_1_IRQn, 0, 0);
    HAL_NVIC_EnableIRQ(EXTI0_1_IRQn);

}

void Error_Handler(void)
{
    __disable_irq();
    while (1)
    {
    }
}
